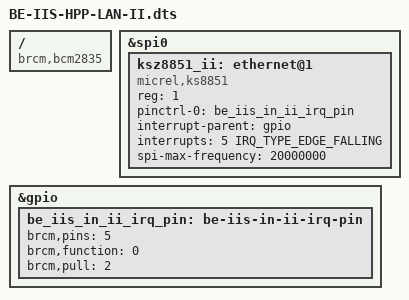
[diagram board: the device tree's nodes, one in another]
// Raspberry Pi DT overlay: Microchip KSZ8851 on SPI0 (CE1)
// IRQ: BCM GPIO5 (falling edge)
// CE1: BCM GPIO7 (falling edge)
// SPI must be enabled in config.txt:
//     dtparam=spi=on
//
// Supported Raspberry Pi models (SPI0-based):
//   - Raspberry Pi Zero / Zero W / Zero 2 W
//   - Raspberry Pi 1 (A/B/B+)
//   - Raspberry Pi 2 (v1.1 / v1.2)
//   - Raspberry Pi 3 (3A+, 3B, 3B+)
//   - Raspberry Pi 4 (4B, 400, CM4)
//   - Raspberry Pi 5
//
// Notes:
//   - Uses SPI0 + CE1
//   - Uses BCM GPIO numbering
//   - Works across bcm2835 / bcm2711 / bcm2712

/dts-v1/;
/plugin/;

#include <dt-bindings/interrupt-controller/irq.h>
#include <dt-bindings/gpio/gpio.h>

/ {
	compatible = "brcm,bcm2835", "brcm,bcm2711", "brcm,bcm2712";

	fragment@0 {
		target = <&spi0>;
		__overlay__ {
			#address-cells = <1>;
			#size-cells = <0>;

			ksz8851_ii: ethernet@1 {
				compatible = "micrel,ks8851";
				reg = <1>;
				
                                pinctrl-names = "default";
                                pinctrl-0 = <&be_iis_in_ii_irq_pin>;
				
				interrupt-parent = <&gpio>;
				interrupts = <5 IRQ_TYPE_EDGE_FALLING>;

				spi-max-frequency = <20000000>;
				status = "okay";
			};
		};
	};

/* GPIO5 as input, pull-up (IRQ pin) */
fragment@2 {
    target = <&gpio>;
    __overlay__ {
        be_iis_in_ii_irq_pin: be-iis-in-ii-irq-pin {
            brcm,pins = <5>;
            brcm,function = <0>;
            brcm,pull = <2>;
        };
    };
};

	__overrides__ {
		speed   = <&ksz8851_ii>, "spi-max-frequency:0";
	};
};

/*
 * Brechel Electronic
 * Industrial Interface Systems
 *
 * Product: BE-IIS-HPP-CAN-FD-SIC
 *
 * Website:
 * https://www.be-iis.eu
 *
 * Digi-Key:
 * 
 */

